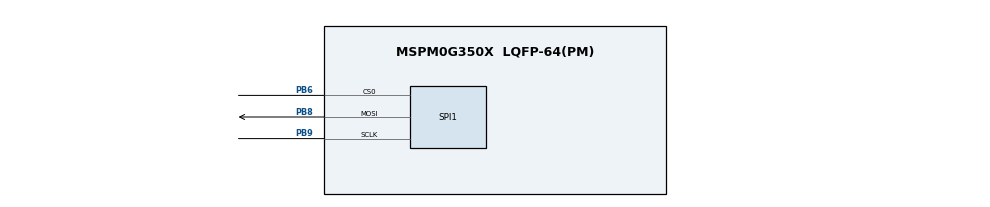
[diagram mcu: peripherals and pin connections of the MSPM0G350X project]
/**
 * @cliArgs --device "MSPM0G350X" --part "Default" --package "LQFP-64(PM)" --product "mspm0_sdk@2.11.00.07"
 * @versions {"tool":"1.26.2+4477"}
 */

/**
 * Import the modules used in this configuration.
 */
const GPIO   = scripting.addModule("/ti/driverlib/GPIO", {}, false);
const GPIO1  = GPIO.addInstance();
const SPI    = scripting.addModule("/ti/driverlib/SPI", {}, false);
const SPI1   = SPI.addInstance();
const SYSCTL = scripting.addModule("/ti/driverlib/SYSCTL");

/**
 * Write custom configuration values to the imported modules.
 */
GPIO1.$name                          = "GPIO_TFT_CTRL";
GPIO1.associatedPins.create(2);
GPIO1.associatedPins[0].$name        = "TFT_DC";
GPIO1.associatedPins[0].assignedPort = "PORTB";
GPIO1.associatedPins[0].assignedPin  = "15";
GPIO1.associatedPins[1].$name        = "TFT_BLK";
GPIO1.associatedPins[1].initialValue = "SET";
GPIO1.associatedPins[1].assignedPort = "PORTB";
GPIO1.associatedPins[1].assignedPin  = "12";

const Board = scripting.addModule("/ti/driverlib/Board", {}, false);

SPI1.$name                              = "SPI_TFT";
SPI1.peripheral.$assign                 = "SPI1";
SPI1.peripheral.sclkPin.$assign         = "PB9";
SPI1.peripheral.mosiPin.$assign         = "PB8";
SPI1.peripheral.cs0Pin.$assign          = "PB6";
SPI1.sclkPinConfig.$name                = "ti_driverlib_gpio_GPIOPinGeneric0";
SPI1.sclkPinConfig.direction            = scripting.forceWrite("OUTPUT");
SPI1.sclkPinConfig.onlyInternalResistor = scripting.forceWrite(false);
SPI1.sclkPinConfig.passedPeripheralType = scripting.forceWrite("Digital");
SPI1.sclkPinConfig.enableConfig         = true;
SPI1.mosiPinConfig.$name                = "ti_driverlib_gpio_GPIOPinGeneric1";
SPI1.mosiPinConfig.direction            = scripting.forceWrite("OUTPUT");
SPI1.mosiPinConfig.hideOutputInversion  = scripting.forceWrite(false);
SPI1.mosiPinConfig.onlyInternalResistor = scripting.forceWrite(false);
SPI1.mosiPinConfig.passedPeripheralType = scripting.forceWrite("Digital");
SPI1.mosiPinConfig.enableConfig         = true;
SPI1.misoPinConfig.$name                = "ti_driverlib_gpio_GPIOPinGeneric2";
SPI1.misoPinConfig.onlyInternalResistor = scripting.forceWrite(false);
SPI1.misoPinConfig.passedPeripheralType = scripting.forceWrite("Digital");
SPI1.cs0PinConfig.$name                 = "ti_driverlib_gpio_GPIOPinGeneric3";
SPI1.cs0PinConfig.direction             = scripting.forceWrite("OUTPUT");
SPI1.cs0PinConfig.hideOutputInversion   = scripting.forceWrite(false);
SPI1.cs0PinConfig.onlyInternalResistor  = scripting.forceWrite(false);
SPI1.cs0PinConfig.passedPeripheralType  = scripting.forceWrite("Digital");
SPI1.cs0PinConfig.enableConfig          = true;

SYSCTL.forceDefaultClkConfig = true;

/**
 * Pinmux solution for unlocked pins/peripherals. This ensures that minor changes to the automatic solver in a future
 * version of the tool will not impact the pinmux you originally saw.  These lines can be completely deleted in order to
 * re-solve from scratch.
 */
GPIO1.associatedPins[0].pin.$suggestSolution = "PB15";
GPIO1.associatedPins[1].pin.$suggestSolution = "PB12";
Board.peripheral.$suggestSolution            = "DEBUGSS";
Board.peripheral.swclkPin.$suggestSolution   = "PA20";
Board.peripheral.swdioPin.$suggestSolution   = "PA19";
SPI1.peripheral.misoPin.$suggestSolution     = "PA16";
SYSCTL.peripheral.$suggestSolution           = "SYSCTL";
